AUTOSAR XML (schema 4-2-2)
package /AUTOLIV/SoftwareComponents/EOL
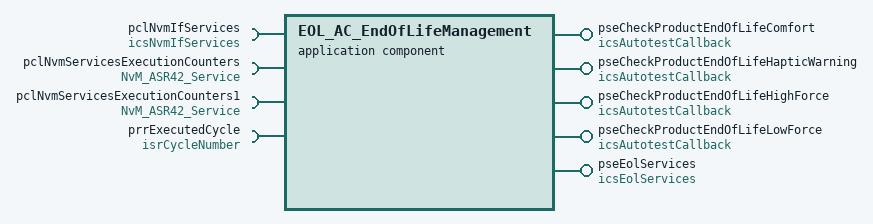
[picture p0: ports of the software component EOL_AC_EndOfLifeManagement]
  application sw component type EOL_AC_EndOfLifeManagement: category=SWC
    4 x require port:
      pclNvmIfServices: required-com-specs=[GetNvmBlockStatus, GetNvmBlockLength], required-interface=icsNvmIfServices
      pclNvmServicesExecutionCounters: required-interface=NvM_ASR42_Service
        required-com-specs:
          GetErrorStatus
          SetDataIndex
          GetDataIndex
          SetRamBlockStatus
          ReadBlock
          WriteBlock
          RestoreBlockDefaults
          EraseBlock
          InvalidateNvBlock
      pclNvmServicesExecutionCounters1: required-interface=NvM_ASR42_Service
        required-com-specs:
          GetErrorStatus
          SetDataIndex
          GetDataIndex
          SetRamBlockStatus
          ReadBlock
          WriteBlock
          RestoreBlockDefaults
          EraseBlock
          InvalidateNvBlock
      prrExecutedCycle: nonqueued-receiver-com-spec{data-element=u8CycleNumber, uses-end-to-end-protection=0, init-value=constant-reference=APPLINIT_KU8_CYCLE_NUMBER_NONE}, required-interface=isrCycleNumber
    5 x provide port:
      pseCheckProductEndOfLifeComfort: server-com-spec{operation=AutotestCallback, queue-length=1}, provided-interface=icsAutotestCallback
      pseCheckProductEndOfLifeHapticWarning: server-com-spec{operation=AutotestCallback, queue-length=1}, provided-interface=icsAutotestCallback
      pseCheckProductEndOfLifeHighForce: server-com-spec{operation=AutotestCallback, queue-length=1}, provided-interface=icsAutotestCallback
      pseCheckProductEndOfLifeLowForce: server-com-spec{operation=AutotestCallback, queue-length=1}, provided-interface=icsAutotestCallback
      pseEolServices: server-com-spec{operation=SetCycleCounterDatasetIndex, queue-length=1}, provided-interface=icsEolServices
